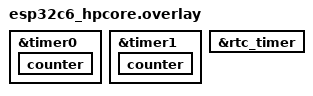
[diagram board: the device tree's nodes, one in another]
/*
 * Copyright (c) 2025 Espressif Systems (Shanghai) Co., Ltd.
 *
 * SPDX-License-Identifier: Apache-2.0
 */

&timer0 {
	status = "okay";
	counter {
		status = "okay";
	};
};

&timer1 {
	status = "okay";
	counter {
		status = "okay";
	};
};

&rtc_timer {
	status = "okay";
};
